VERSION ""

NS_ :

BS_:

BU_: RMC HMI DCU

BO_ 258 COMM_ADReq: 8 Vector__XXX
 SG_ COMM_Watchdog : 56|8@1+ (1,0) [0|255] "" Vector__XXX
 SG_ COMM_ADEnReq : 0|2@1+ (1,0) [0|3] "" Vector__XXX

BO_ 274 DCU_SupervisorDebug: 8 DCU
 SG_ TransitionCaseLong : 8|8@1+ (1,0) [0|255] "" Vector__XXX
 SG_ TransitionCaseLat : 0|8@1+ (1,0) [0|255] "" Vector__XXX

BO_ 288 RMC_State: 8 RMC
 SG_ RMC_SV_Watchdog : 56|8@1+ (1,0) [0|255] "" Vector__XXX
 SG_ RMC_ADState : 0|4@1+ (1,0) [0|15] "" Vector__XXX

BO_ 257 HMI_ADReq: 8 HMI
 SG_ HMI_Watchdog : 56|8@1+ (1,0) [0|255] "" Vector__XXX
 SG_ HMI_ADEnReq : 0|2@1+ (1,0) [0|3] "" Vector__XXX

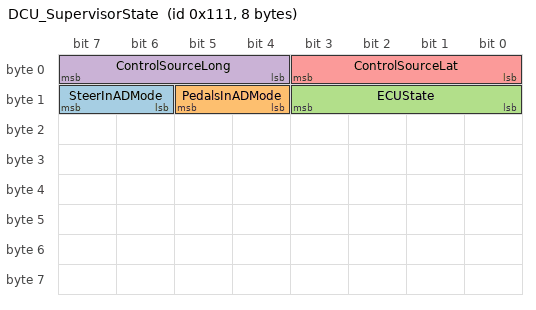
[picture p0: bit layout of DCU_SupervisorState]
BO_ 273 DCU_SupervisorState: 8 DCU
 SG_ SteerInADMode : 14|2@1+ (1,0) [0|3] "" Vector__XXX
 SG_ PedalsInADMode : 12|2@1+ (1,0) [0|3] "" Vector__XXX
 SG_ ECUState : 8|4@1+ (1,0) [0|15] "" Vector__XXX
 SG_ ControlSourceLong : 4|4@1+ (1,0) [0|15] "" Vector__XXX
 SG_ ControlSourceLat : 0|4@1+ (1,0) [0|15] "" Vector__XXX

CM_ SG_ 258 COMM_Watchdog "Increment counter";
CM_ SG_ 258 COMM_ADEnReq "AD mode enable demand (0 - off, 1 - on)";
CM_ SG_ 257 HMI_Watchdog "Increment counter";
CM_ SG_ 257 HMI_ADEnReq "AD mode enable demand (0 - off, 1 - on)";
CM_ SG_ 273 SteerInADMode "State of steer control (0 - not in AD, 1 - in AD)";
CM_ SG_ 273 PedalsInADMode "State of pedals control (0 - not in AD, 1 - in AD)";
CM_ SG_ 273 ECUState "Active ECU mode";
BA_DEF_  "DBName" STRING ;
BA_DEF_ SG_  "SigType" ENUM  "Default","Range","RangeSigned","ASCII","Discrete","Control","ReferencePGN","DTC","StringDelimiter","StringLength","StringLengthControl","MessageCounter","MessageChecksum";
BA_DEF_ SG_  "GenSigSendType" ENUM  "Cyclic","OnWrite","OnWriteWithRepetition","OnChange","OnChangeWithRepetition","IfActive","IfActiveWithRepetition","NoSigSendType";
BA_DEF_ SG_  "GenSigILSupport" ENUM  "No","Yes";
BA_DEF_ SG_  "GenSigEVName" STRING ;
BA_DEF_ BO_  "GenMsgILSupport" ENUM  "No","Yes";
BA_DEF_ BO_  "GenMsgRequestable" INT 0 1;
BA_DEF_ BO_  "GenMsgSendType" ENUM  "cyclic","NotUsed","NotUsed","NotUsed","NotUsed","NotUsed","NotUsed","IfActive","noMsgSendType";
BA_DEF_ BO_  "VFrameFormat" ENUM  "StandardCAN","ExtendedCAN","reserved","J1939PG";
BA_DEF_ BO_  "GenMsgCycleTime" INT 0 3600000;
BA_DEF_ BU_  "NmStationAddress" INT 0 255;
BA_DEF_  "SAE_J1939_DA_SpecVersion" STRING ;
BA_DEF_  "SAE_J1939_81_SpecVersion" STRING ;
BA_DEF_  "DatabaseVersion" STRING ;
BA_DEF_  "BusType" STRING ;
BA_DEF_  "ProtocolType" STRING ;
BA_DEF_  "SAE_J1939_75_SpecVersion" STRING ;
BA_DEF_  "SAE_J1939_21_SpecVersion" STRING ;
BA_DEF_  "SAE_J1939_73_SpecVersion" STRING ;
BA_DEF_  "SAE_J1939_71_SpecVersion" STRING ;
BA_DEF_DEF_  "DBName" "";
BA_DEF_DEF_  "SigType" "Default";
BA_DEF_DEF_  "GenSigSendType" "NoSigSendType";
BA_DEF_DEF_  "GenSigILSupport" "Yes";
BA_DEF_DEF_  "GenSigEVName" "Env@Nodename_@Signame";
BA_DEF_DEF_  "GenMsgILSupport" "Yes";
BA_DEF_DEF_  "GenMsgRequestable" 1;
BA_DEF_DEF_  "GenMsgSendType" "noMsgSendType";
BA_DEF_DEF_  "VFrameFormat" "J1939PG";
BA_DEF_DEF_  "GenMsgCycleTime" 0;
BA_DEF_DEF_  "NmStationAddress" 254;
BA_DEF_DEF_  "SAE_J1939_DA_SpecVersion" "";
BA_DEF_DEF_  "SAE_J1939_81_SpecVersion" "";
BA_DEF_DEF_  "DatabaseVersion" "";
BA_DEF_DEF_  "BusType" "";
BA_DEF_DEF_  "ProtocolType" "";
BA_DEF_DEF_  "SAE_J1939_75_SpecVersion" "";
BA_DEF_DEF_  "SAE_J1939_21_SpecVersion" "";
BA_DEF_DEF_  "SAE_J1939_73_SpecVersion" "";
BA_DEF_DEF_  "SAE_J1939_71_SpecVersion" "";
BA_ "SAE_J1939_71_SpecVersion" "2012-10";
BA_ "SAE_J1939_73_SpecVersion" "2012-10";
BA_ "SAE_J1939_21_SpecVersion" "2006-10";
BA_ "SAE_J1939_75_SpecVersion" "2012-05";
BA_ "ProtocolType" "J1939";
BA_ "BusType" "CAN";
BA_ "DatabaseVersion" "8.5";
BA_ "SAE_J1939_81_SpecVersion" "2012-05";
BA_ "SAE_J1939_DA_SpecVersion" "2015-01";
BA_ "DBName" "Arrival_DCU_P2";
BA_ "NmStationAddress" BU_ DCU 100;
BA_ "GenMsgSendType" BO_ 258 0;
BA_ "VFrameFormat" BO_ 258 0;
BA_ "GenMsgCycleTime" BO_ 258 50;
BA_ "GenMsgSendType" BO_ 274 0;
BA_ "VFrameFormat" BO_ 274 0;
BA_ "GenMsgCycleTime" BO_ 274 10;
BA_ "GenMsgCycleTime" BO_ 288 10;
BA_ "VFrameFormat" BO_ 288 0;
BA_ "GenMsgSendType" BO_ 288 0;
BA_ "GenMsgSendType" BO_ 257 0;
BA_ "VFrameFormat" BO_ 257 0;
BA_ "GenMsgCycleTime" BO_ 257 50;
BA_ "VFrameFormat" BO_ 273 0;
BA_ "GenMsgSendType" BO_ 273 0;
BA_ "GenMsgCycleTime" BO_ 273 10;
BA_ "GenSigSendType" SG_ 273 ECUState 0;
VAL_ 258 COMM_ADEnReq 1 "COMM AD Enable request ON" 0 "COMM AD Enable request OFF" ;
VAL_ 257 HMI_ADEnReq 1 "HMI AD Enable request ON" 0 "HMI AD Enable request OFF" ;
VAL_ 273 SteerInADMode 1 "Steer in AD mode" 0 "Steer not in AD mode" ;
VAL_ 273 PedalsInADMode 1 "Pedals in AD mode" 0 "Pedals not in AD mode" ;
VAL_ 273 ECUState 2 "SafeStop" 1 "AD" 0 "Driver" ;
VAL_ 273 ControlSourceLong 2 "SafeStop" 1 "AD" 0 "Driver" ;
VAL_ 273 ControlSourceLat 2 "SafeStop" 1 "AD" 0 "Driver" ;
